# HSM_TC3xx register map
Vendor: Infineon; Series: AURIX TC3xx; File version: 2.0
CPU: CM3 r2p0, little endian, MPU, no FPU, 3 interrupt priority bits
Registers are 32-bit, read-write, no defined reset value unless marked. A register's access mark holds for its fields unless they carry their own. Offsets are from the block's base; [hi:lo] are bit positions.

## HSM_SCB — Cortex-M3 System Control Block (ARMv7-M, HSM TS 2.2).
Base 0xE000ED00
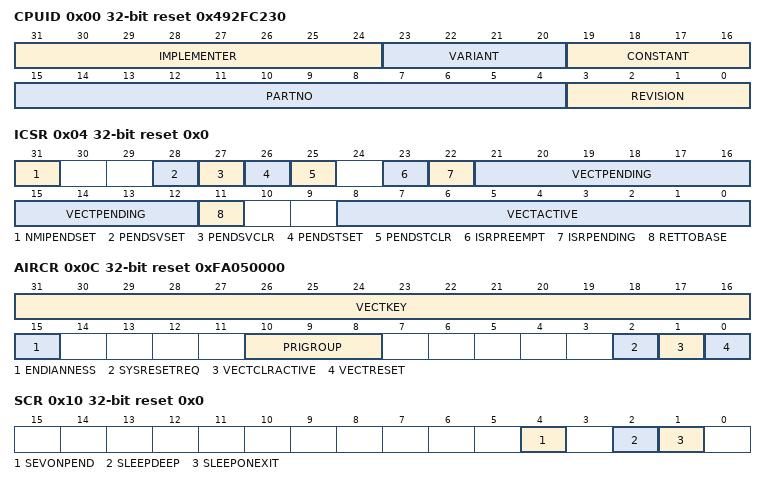
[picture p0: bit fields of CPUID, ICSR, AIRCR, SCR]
0x00 CPUID ro reset 0x492FC230 (reset mask 0xFFFFFFF0) — CPUID Base Register
  [31:24] IMPLEMENTER — Implementer (49H on the HSM)
  [23:20] VARIANT — Variant (r2)
  [19:16] CONSTANT — Architecture (FH)
  [15:4] PARTNO — Part number (C23H = Cortex-M3)
  [3:0] REVISION — Revision (p0)
0x04 ICSR reset 0x0 — Interrupt Control and State Register
  [31] NMIPENDSET — NMI pending
  [28] PENDSVSET — PendSV pending
  [27] PENDSVCLR — Clear PendSV pending. Reads as 0.
  [26] PENDSTSET — SysTick pending
  [25] PENDSTCLR — Clear SysTick pending. Reads as 0.
  [23] ISRPREEMPT ro — Pending exception serviced on exit from debug halt
  [22] ISRPENDING ro — External interrupt pending
  [21:12] VECTPENDING ro — Highest priority pending exception
  [11] RETTOBASE ro — No other active exception
  [8:0] VECTACTIVE ro — Active exception number
0x08 VTOR reset 0x0 — Vector Table Offset Register (bits 31:30 added for vector tables in flash, HSM TS 2.3.2)
  [31:7] TBLOFF — Vector table base address bits 31:7
0x0C AIRCR reset 0xFA050000 — Application Interrupt and Reset Control Register. Do not set SYSRESETREQ or VECTRESET on the HSM (undefined behaviour, HSM TS 2.2.5).
  [31:16] VECTKEY — Write 05FAH; reads FA05H
  [15] ENDIANNESS ro — Data endianness (0: little)
  [10:8] PRIGROUP — Priority grouping
  [2] SYSRESETREQ — System reset request (do not use)
  [1] VECTCLRACTIVE — Clear active state (debug only)
  [0] VECTRESET — Local reset (do not use)
0x10 SCR reset 0x0 — System Control Register
  [4] SEVONPEND — Send event on pending
  [2] SLEEPDEEP — Deep sleep (no effect on the HSM except SysTick stop)
  [1] SLEEPONEXIT — Sleep on exit from handler
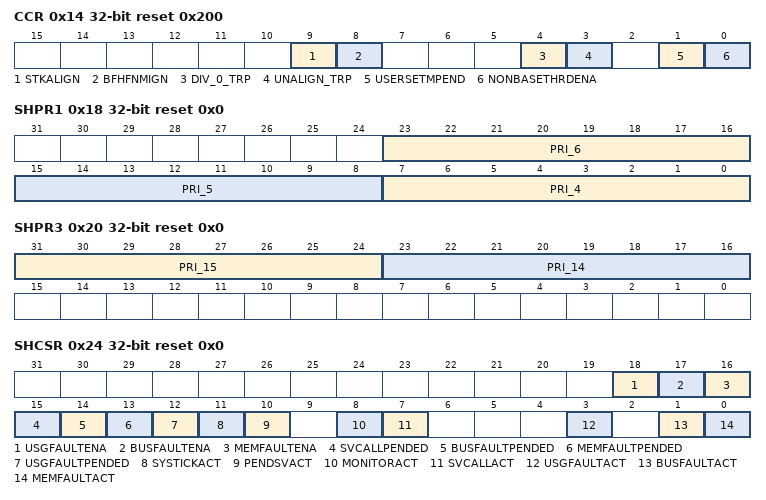
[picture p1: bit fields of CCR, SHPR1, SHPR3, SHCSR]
0x14 CCR reset 0x200 — Configuration and Control Register
  [9] STKALIGN — 8-byte stack alignment on exception entry
  [8] BFHFNMIGN — Ignore precise bus faults in HardFault/NMI
  [4] DIV_0_TRP — Trap divide by zero
  [3] UNALIGN_TRP — Trap unaligned accesses
  [1] USERSETMPEND — Unprivileged access to STIR
  [0] NONBASETHRDENA — Enter thread mode with active exceptions
0x18 SHPR1 reset 0x0 — System Handler Priority Register 1
  [23:16] PRI_6 — UsageFault priority
  [15:8] PRI_5 — BusFault priority
  [7:0] PRI_4 — MemManage priority
0x1C SHPR2 reset 0x0 — System Handler Priority Register 2
  [31:24] PRI_11 — SVCall priority
0x20 SHPR3 reset 0x0 — System Handler Priority Register 3
  [31:24] PRI_15 — SysTick priority
  [23:16] PRI_14 — PendSV priority
0x24 SHCSR reset 0x0 — System Handler Control and State Register
  [18] USGFAULTENA — UsageFault enable
  [17] BUSFAULTENA — BusFault enable
  [16] MEMFAULTENA — MemManage enable
  [15] SVCALLPENDED — SVCall pending
  [14] BUSFAULTPENDED — BusFault pending
  [13] MEMFAULTPENDED — MemManage pending
  [12] USGFAULTPENDED — UsageFault pending
  [11] SYSTICKACT — SysTick active
  [10] PENDSVACT — PendSV active
  [8] MONITORACT — Debug monitor active
  [7] SVCALLACT — SVCall active
  [3] USGFAULTACT — UsageFault active
  [1] BUSFAULTACT — BusFault active
  [0] MEMFAULTACT — MemManage active
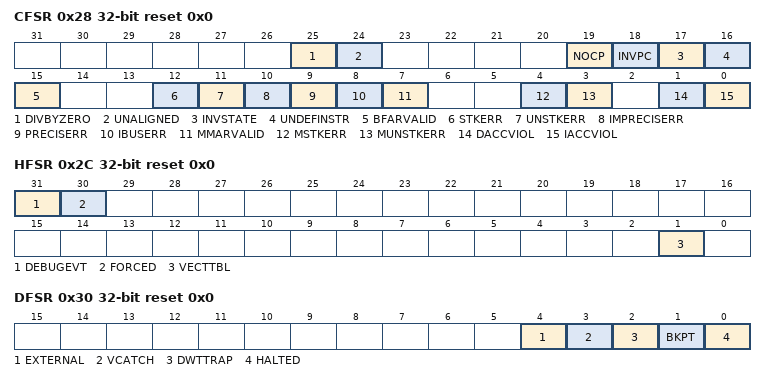
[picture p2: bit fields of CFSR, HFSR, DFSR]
0x28 CFSR reset 0x0 write-1-clears — Configurable Fault Status Register (MMFSR, BFSR, UFSR; write 1 to clear)
  [25] DIVBYZERO — Divide by zero UsageFault
  [24] UNALIGNED — Unaligned access UsageFault
  [19] NOCP — No coprocessor UsageFault
  [18] INVPC — Invalid PC load UsageFault
  [17] INVSTATE — Invalid state UsageFault
  [16] UNDEFINSTR — Undefined instruction UsageFault
  [15] BFARVALID
  [12] STKERR — BusFault on exception entry stacking
  [11] UNSTKERR — BusFault on exception return unstacking
  [10] IMPRECISERR — Imprecise data bus error
  [9] PRECISERR — Precise data bus error
  [8] IBUSERR — Instruction bus error
  [7] MMARVALID — MMFAR valid
  [4] MSTKERR — MemManage fault on stacking
  [3] MUNSTKERR — MemManage fault on unstacking
  [1] DACCVIOL — Data access violation
  [0] IACCVIOL — Instruction access violation
0x2C HFSR reset 0x0 write-1-clears — HardFault Status Register (write 1 to clear)
  [31] DEBUGEVT — Debug event
  [30] FORCED — Forced HardFault (escalated)
  [1] VECTTBL — Vector table read fault
0x30 DFSR ro reset 0x0 — Debug Fault Status Register (cleared by the debug server; read-only here)
  [4] EXTERNAL — External debug request
  [3] VCATCH — Vector catch
  [2] DWTTRAP — DWT match
  [1] BKPT — Breakpoint
  [0] HALTED — Halt request or step
0x34 MMFAR — MemManage Fault Address Register
  [31:0] ADDRESS — Fault address (valid if CFSR.MMARVALID)
0x38 BFAR — BusFault Address Register
  [31:0] ADDRESS — Fault address (valid if CFSR.BFARVALID)
0x3C AFSR reset 0x0 — Auxiliary Fault Status Register
  [31:0] IMPDEF — Implementation defined
